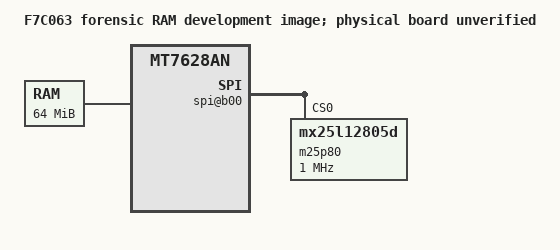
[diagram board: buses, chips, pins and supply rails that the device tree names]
/dts-v1/;
/include/ "mt7628an.dtsi"

/ {
 compatible = "mediatek,mt7628an-eval-board", "mediatek,mt7628an-soc";
 model = "F7C063 forensic RAM development image; physical board unverified";
 memory@0 { device_type = "memory"; reg = <0 0x4000000>; };
 chosen { bootargs = "console=ttyS0,57600 rdinit=/init init=/init panic=0"; };
 palmbus@10000000 {
  /delete-node/ watchdog@120;
  /delete-node/ gpio@600;
  /delete-node/ uart1@d00;
  /delete-node/ uart2@e00;
  spi@b00 {
   #size-cells = <0>;
   status = "okay";
   m25p80@0 {
    compatible = "mx25l12805d";
    linux,modalias = "m25p80", "mx25l12805d";
    reg = <0>;
    spi-max-frequency = <1000000>;
    /* Whole JEDEC-detected device only; no assumed partition write ranges. */
   };
  };
 };
 /delete-node/ usbphy@10120000;
 /delete-node/ sdhci@10130000;
 /delete-node/ ehci@101c0000;
 /delete-node/ ohci@101c1000;
 /delete-node/ ethernet@10100000;
 /delete-node/ esw@10110000;
 /delete-node/ pcie@10140000;
};
